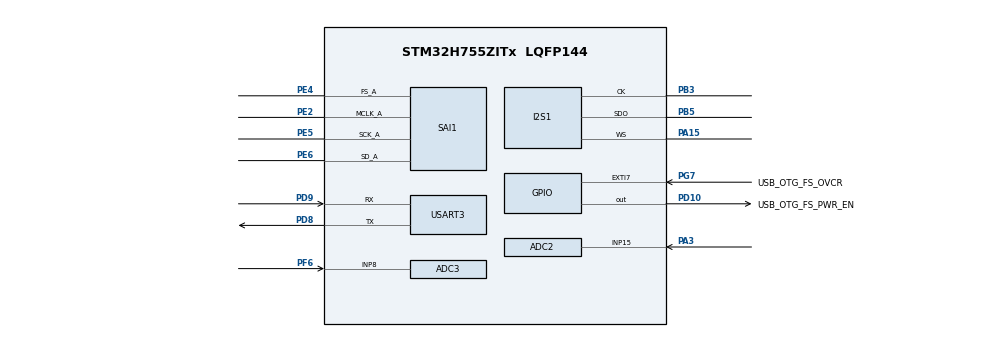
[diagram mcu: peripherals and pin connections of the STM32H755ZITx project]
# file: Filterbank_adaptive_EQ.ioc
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ADC2.Channel-2\#ChannelRegularConversion=ADC_CHANNEL_15
ADC2.NbrOfConversionFlag=1
ADC2.OffsetNumber-2\#ChannelRegularConversion=ADC_OFFSET_NONE
ADC2.OffsetSignedSaturation-2\#ChannelRegularConversion=DISABLE
ADC2.Rank-2\#ChannelRegularConversion=1
ADC2.SamplingTime-2\#ChannelRegularConversion=ADC_SAMPLETIME_1CYCLE_5
ADC3.Channel-0\#ChannelRegularConversion=ADC_CHANNEL_8
ADC3.NbrOfConversionFlag=1
ADC3.OffsetNumber-0\#ChannelRegularConversion=ADC_OFFSET_NONE
ADC3.OffsetSignedSaturation-0\#ChannelRegularConversion=DISABLE
ADC3.Rank-0\#ChannelRegularConversion=1
ADC3.SamplingTime-0\#ChannelRegularConversion=ADC_SAMPLETIME_1CYCLE_5
Bdma.ADC3.0.Direction=DMA_PERIPH_TO_MEMORY
Bdma.ADC3.0.EventEnable=DISABLE
Bdma.ADC3.0.Instance=BDMA_Channel0
Bdma.ADC3.0.MemDataAlignment=DMA_MDATAALIGN_HALFWORD
Bdma.ADC3.0.MemInc=DMA_MINC_ENABLE
Bdma.ADC3.0.Mode=DMA_CIRCULAR
Bdma.ADC3.0.PeriphDataAlignment=DMA_PDATAALIGN_HALFWORD
Bdma.ADC3.0.PeriphInc=DMA_PINC_DISABLE
Bdma.ADC3.0.Polarity=HAL_DMAMUX_REQ_GEN_RISING
Bdma.ADC3.0.Priority=DMA_PRIORITY_LOW
Bdma.ADC3.0.RequestNumber=1
Bdma.ADC3.0.SignalID=NONE
Bdma.ADC3.0.SyncEnable=DISABLE
Bdma.ADC3.0.SyncPolarity=HAL_DMAMUX_SYNC_NO_EVENT
Bdma.ADC3.0.SyncRequestNumber=1
Bdma.ADC3.0.SyncSignalID=NONE
Bdma.Request0=ADC3
Bdma.RequestsNb=1
CortexM4.IPs=FATFS_M4\:I,FREERTOS_M4\:I,IWDG2\:I,RCC,WWDG2\:I,DMA,BDMA,MDMA,NVIC2\:I,USART3,DEBUG,PDM2PCM_M4\:I,PWR,RESMGR_UTILITY,SYS_M4\:I,USB_DEVICE_M4\:I,USB_HOST_M4\:I,CORTEX_M4\:I,GPIO,OPENAMP_M4\:I,VREFBUF,NUCLEO-H755ZI-Q
CortexM7.IPs=FATFS_M7\:I,FREERTOS_M7\:I,IWDG1\:I,RCC\:I,WWDG1\:I,DMA\:I,BDMA\:I,MDMA\:I,NVIC1\:I,USART3\:I,USB_OTG_FS\:I,USB_OTG_FS1\:I,SYS\:I,CORTEX_M7\:I,DEBUG\:I,PDM2PCM_M7\:I,PWR\:I,RESMGR_UTILITY\:I,USB_DEVICE_M7\:I,USB_HOST_M7\:I,GPIO\:I,OPENAMP_M7\:I,VREFBUF\:I,NUCLEO-H755ZI-Q\:I,SAI1\:I,I2S1\:I,ADC3\:I,ADC2\:I
Dma.ADC2.2.Direction=DMA_PERIPH_TO_MEMORY
Dma.ADC2.2.EventEnable=DISABLE
Dma.ADC2.2.FIFOMode=DMA_FIFOMODE_DISABLE
Dma.ADC2.2.Instance=DMA1_Stream3
Dma.ADC2.2.MemDataAlignment=DMA_MDATAALIGN_HALFWORD
Dma.ADC2.2.MemInc=DMA_MINC_ENABLE
Dma.ADC2.2.Mode=DMA_CIRCULAR
Dma.ADC2.2.PeriphDataAlignment=DMA_PDATAALIGN_HALFWORD
Dma.ADC2.2.PeriphInc=DMA_PINC_DISABLE
Dma.ADC2.2.Polarity=HAL_DMAMUX_REQ_GEN_RISING
Dma.ADC2.2.Priority=DMA_PRIORITY_LOW
Dma.ADC2.2.RequestNumber=1
Dma.ADC2.2.SignalID=NONE
Dma.ADC2.2.SyncEnable=DISABLE
Dma.ADC2.2.SyncPolarity=HAL_DMAMUX_SYNC_NO_EVENT
Dma.ADC2.2.SyncRequestNumber=1
Dma.ADC2.2.SyncSignalID=NONE
Dma.Request0=SAI1_A
Dma.Request1=SPI1_TX
Dma.Request2=ADC2
Dma.SAI1_A.0.Direction=DMA_PERIPH_TO_MEMORY
Dma.SAI1_A.0.EventEnable=DISABLE
Dma.SAI1_A.0.FIFOMode=DMA_FIFOMODE_DISABLE
Dma.SAI1_A.0.Instance=DMA1_Stream0
Dma.SAI1_A.0.MemDataAlignment=DMA_MDATAALIGN_HALFWORD
Dma.SAI1_A.0.MemInc=DMA_MINC_ENABLE
Dma.SAI1_A.0.Mode=DMA_CIRCULAR
Dma.SAI1_A.0.PeriphDataAlignment=DMA_PDATAALIGN_HALFWORD
Dma.SAI1_A.0.PeriphInc=DMA_PINC_DISABLE
Dma.SAI1_A.0.Polarity=HAL_DMAMUX_REQ_GEN_RISING
Dma.SAI1_A.0.Priority=DMA_PRIORITY_VERY_HIGH
Dma.SAI1_A.0.RequestNumber=1
Dma.SAI1_A.0.SignalID=NONE
Dma.SAI1_A.0.SyncEnable=DISABLE
Dma.SAI1_A.0.SyncPolarity=HAL_DMAMUX_SYNC_NO_EVENT
Dma.SAI1_A.0.SyncRequestNumber=1
Dma.SAI1_A.0.SyncSignalID=NONE
Dma.SPI1_TX.1.Direction=DMA_MEMORY_TO_PERIPH
Dma.SPI1_TX.1.EventEnable=DISABLE
Dma.SPI1_TX.1.FIFOMode=DMA_FIFOMODE_DISABLE
Dma.SPI1_TX.1.Instance=DMA1_Stream1
Dma.SPI1_TX.1.MemDataAlignment=DMA_MDATAALIGN_HALFWORD
Dma.SPI1_TX.1.MemInc=DMA_MINC_ENABLE
Dma.SPI1_TX.1.Mode=DMA_CIRCULAR
Dma.SPI1_TX.1.PeriphDataAlignment=DMA_PDATAALIGN_HALFWORD
Dma.SPI1_TX.1.PeriphInc=DMA_PINC_DISABLE
Dma.SPI1_TX.1.Polarity=HAL_DMAMUX_REQ_GEN_RISING
Dma.SPI1_TX.1.Priority=DMA_PRIORITY_VERY_HIGH
Dma.SPI1_TX.1.RequestNumber=1
Dma.SPI1_TX.1.SignalID=NONE
Dma.SPI1_TX.1.SyncEnable=DISABLE
Dma.SPI1_TX.1.SyncPolarity=HAL_DMAMUX_SYNC_NO_EVENT
Dma.SPI1_TX.1.SyncRequestNumber=1
Dma.SPI1_TX.1.SyncSignalID=NONE
I2S1.AudioFreq=I2S_AUDIOFREQ_44K
I2S1.CPOL=I2S_CPOL_LOW
I2S1.DataFormat=I2S_DATAFORMAT_16B_EXTENDED
I2S1.ErrorAudioFreq=0.22 %
I2S1.Instance=SPI$Index
I2S1.RealAudioFreq=44.101 KHz
Mcu.Family=STM32H7
Mcu.Name=STM32H755ZITx
Mcu.Package=LQFP144
NVIC1.BDMA_Channel0_IRQn=true\:0\:0\:false\:false\:true\:false\:true\:true
NVIC1.DMA1_Stream0_IRQn=true\:0\:0\:false\:false\:true\:false\:true\:true
NVIC1.DMA1_Stream1_IRQn=true\:0\:0\:false\:false\:true\:false\:true\:true
NVIC1.DMA1_Stream3_IRQn=true\:0\:0\:false\:false\:true\:false\:true\:true
NVIC1.PriorityGroup=NVIC_PRIORITYGROUP_4
NVIC2.PriorityGroup=NVIC_PRIORITYGROUP_4
PA1.PinAttribute=CortexM4
PA1.Signal=ETH_REF_CLK
PA11.PinAttribute=CortexM7
PA11.Signal=USB_OTG_FS_DM
PA12.PinAttribute=CortexM7
PA12.Signal=USB_OTG_FS_DP
PA15\ (JTDI).Mode=Half_Duplex_Master_Tx
PA15\ (JTDI).PinAttribute=CortexM7
PA15\ (JTDI).Signal=I2S1_WS
PA2.PinAttribute=CortexM4
PA2.Signal=ETH_MDIO
PA3.PinAttribute=CortexM7
PA3.Signal=ADCx_INP15
PA7.PinAttribute=CortexM4
PA7.Signal=ETH_CRS_DV
PA8.PinAttribute=CortexM7
PA8.Signal=USB_OTG_FS_SOF
PA9.PinAttribute=CortexM7
PA9.Signal=USB_OTG_FS_VBUS
PB10.PinAttribute=CortexM7
PB10.Signal=I2S2_CK
PB15.PinAttribute=CortexM7
PB15.Signal=I2S2_SDO
PB3\ (JTDO/TRACESWO).Mode=Half_Duplex_Master_Tx
PB3\ (JTDO/TRACESWO).PinAttribute=CortexM7
PB3\ (JTDO/TRACESWO).Signal=I2S1_CK
PB4\ (NJTRST).PinAttribute=CortexM7
PB4\ (NJTRST).Signal=I2S2_WS
PB5.Mode=Half_Duplex_Master_Tx
PB5.PinAttribute=CortexM7
PB5.Signal=I2S1_SDO
PC14-OSC32_IN\ (OSC32_IN).PinAttribute=Free
PC14-OSC32_IN\ (OSC32_IN).Signal=RCC_OSC32_IN
PC15-OSC32_OUT\ (OSC32_OUT).PinAttribute=Free
PC15-OSC32_OUT\ (OSC32_OUT).Signal=RCC_OSC32_OUT
PC5.PinAttribute=CortexM4
PC5.Signal=ETH_RXD1
PD10.GPIO_Label=USB_OTG_FS_PWR_EN
PD10.PinAttribute=Free
PD10.Signal=GPIO_Output
PD11.PinAttribute=CortexM7
PD11.Signal=SAI2_SD_A
PD12.PinAttribute=CortexM7
PD12.Signal=SAI2_FS_A
PD13.PinAttribute=CortexM7
PD13.Signal=SAI2_SCK_A
PD8.Mode=Asynchronous
PD8.PinAttribute=CortexM7
PD8.Signal=USART3_TX
PD9.Mode=Asynchronous
PD9.PinAttribute=CortexM7
PD9.Signal=USART3_RX
PE2.GPIO_Speed=GPIO_SPEED_FREQ_VERY_HIGH
PE2.Mode=SAI_A_MasterWithClock
PE2.PinAttribute=CortexM7
PE2.Signal=SAI1_MCLK_A
PE4.GPIO_Speed=GPIO_SPEED_FREQ_VERY_HIGH
PE4.Mode=SAI_A_MasterWithClock
PE4.PinAttribute=CortexM7
PE4.Signal=SAI1_FS_A
PE5.GPIO_Speed=GPIO_SPEED_FREQ_VERY_HIGH
PE5.Mode=SAI_A_MasterWithClock
PE5.PinAttribute=CortexM7
PE5.Signal=SAI1_SCK_A
PE6.GPIO_Speed=GPIO_SPEED_FREQ_VERY_HIGH
PE6.Mode=SAI_A_MasterWithClock
PE6.PinAttribute=CortexM7
PE6.Signal=SAI1_SD_A
PF6.Mode=IN8-Single-Ended
PF6.PinAttribute=CortexM7
PF6.Signal=ADC3_INP8
PG11.PinAttribute=CortexM4
PG11.Signal=ETH_TX_EN
PG13.PinAttribute=CortexM4
PG13.Signal=ETH_TXD0
PG7.GPIO_Label=USB_OTG_FS_OVCR
PG7.PinAttribute=Free
PG7.Signal=GPXTI7
PH0-OSC_IN\ (PH0).Mode=HSE-External-Oscillator
PH0-OSC_IN\ (PH0).PinAttribute=Free
PH0-OSC_IN\ (PH0).Signal=RCC_OSC_IN
PH1-OSC_OUT\ (PH1).Mode=HSE-External-Oscillator
PH1-OSC_OUT\ (PH1).PinAttribute=Free
PH1-OSC_OUT\ (PH1).Signal=RCC_OSC_OUT
ProjectManager.HeapSize=M4-0x200,M7-0x200
ProjectManager.StackSize=M4-0x400,M7-0x400
ProjectManager.TargetToolchain=STM32CubeIDE
RCC.ADCFreq_Value=80000000
RCC.APB1Freq_Value=35281250
RCC.APB2Freq_Value=70562500
RCC.APB3Freq_Value=70562500
RCC.APB4Freq_Value=70562500
RCC.CortexFreq_Value=141125000
RCC.D1PPRE=RCC_APB3_DIV2
RCC.D2PPRE1=RCC_APB1_DIV4
RCC.D2PPRE2=RCC_APB2_DIV2
RCC.D3PPRE=RCC_APB4_DIV2
RCC.DIVM1=4
RCC.DIVM2=4
RCC.DIVN1=17
RCC.DIVN2=10
RCC.DIVQ1=25
RCC.HCLKFreq_Value=141125000
RCC.HSE_VALUE=8000000
RCC.PLL2FRACN=0
RCC.PLL3FRACN=0
RCC.PLLFRACN=5248
RCC.SYSCLKFreq_VALUE=141125000
RCC.SYSCLKSource=RCC_SYSCLKSOURCE_PLLCLK
RCC.SupplySource=PWR_DIRECT_SMPS_SUPPLY
RCC.USBFreq_Value=11290000
SAI1.AudioFrequency-SAI_A_MasterWithClock=SAI_AUDIO_FREQUENCY_44K
SAI1.AudioMode-SAI_A_MasterWithClock=SAI_MODEMASTER_RX
SAI1.BasicDataSize-SAI_A_MasterWithClock=SAI_PROTOCOL_DATASIZE_16BITEXTENDED
SAI1.ErrorAudioFreq-SAI_A_MasterWithClock=0.0 %
SAI1.InitProtocol-SAI_A_MasterWithClock=Enable
SAI1.Instance-SAI_A_MasterWithClock=SAI$Index_Block_A
SAI1.MClockEnable-SAI_A_MasterWithClock=SAI_MASTERCLOCK_ENABLE
SAI1.RealAudioFreq-SAI_A_MasterWithClock=44.101 KHz
SAI1.VirtualMode-SAI_A_MasterWithClock=VM_MASTER
SAI1.VirtualProtocol-SAI_A_BASIC=VM_BASIC_PROTOCOL
SH.ADCx_INP15.0=ADC2_INP15,IN15-Single-Ended
USART3.VirtualMode-Asynchronous=VM_ASYNC
VP_SAI1_VP_$IpInstance_SAIA_SAI_BASIC.Mode=SAI_A_BASIC
VP_SYS_M4_VS_Systick.Mode=SysTick
board=NUCLEO-H755ZI-Q

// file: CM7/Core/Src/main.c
/* USER CODE BEGIN Header */
/**
 * @file           : main.c
 * @brief          : Audio path and room equalizer control
 */
/* USER CODE END Header */
#include "main.h"
#include "adc.h"
#include "bdma.h"
#include "dma.h"
#include "i2s.h"
#include "sai.h"
#include "usart.h"
#include "gpio.h"

/* USER CODE BEGIN Includes */
#include <math.h>
#include <string.h>
#include <stdio.h>
#include "mic_eq_coeffs.h"   /* generated by Tools/EQ_to_BIQUAD.py */
#include "room_eq.h"
/* USER CODE END Includes */

/* USER CODE BEGIN PD */
/* DMA buffer sizes: circular buffers that are processed half by half (ping-pong) */
#define I2S_HALF_FRAMES         256U                         /* stereo frames per half-buffer */
#define I2S_HALF_SAMPLES        (I2S_HALF_FRAMES * 2U)       /* L+R samples per half-buffer */
#define I2S_BUFFER_SAMPLES      (I2S_HALF_SAMPLES * 2U)      /* both halves */

/* Gain per source in dB (left and right), the output is saturated */
#define MIC_GAIN_DB             2.0f        /* PCM1808, SAI1 A */
#define ADC_GAIN_DB             2.0f        /* analog mics, ADC3 + ADC2 */
/* PCM1808 (SAI1 A: PE2 SCKI, PE4 LRCK, PE5 BCK, PE6 DOUT): audio source, equalized and played.
 * Analog mics (left PF6 / ADC3_INP8, right PA3 / ADC2_INP15): measurement microphones of the room equalizer.
 * B1 (PC13): short press = room adaptation run / freeze (LD2 lit = running), hold 1 s = room equalizer on / off
 *            incl. the manual filters (LD3 lit = off). The PCM1808 / mic correction filters always stay on.
 * Serial terminal (USART3, 115200): see Gain_HandleUart(). */
#define MIC_SRC_I2S             0U       /* PCM1808: source, played */
#define MIC_SRC_ADC             1U       /* analog mics: only measured */
#define MIC_SRC_COUNT           2U
#define ADC_HALF_SAMPLES        I2S_HALF_FRAMES              /* per ADC channel, same block length as SAI */
/* Master output volume in dB, applied after the per-source gains (DAC full scale = 2.1 Vrms per channel) */
#define OUTPUT_GAIN_DB          -5.0f
/* DAC output: I2S1 (PB3 BCK, PA15 LRCK, PB5 DIN), plain stereo: left channel on OUTL, right channel on OUTR. */
#define hi2sOut                 hi2s1
/* Recording marker: a short pulse on both outputs (after the room equalizer, independent of gain and mute) when the
 * adaptation is started (1 pulse) or frozen (2 pulses). A start is delayed until the marker has left the mic frames. */
#define MARKER_FREQ_HZ          19000.0f
#define MARKER_AMP              0.9f                         /* peak, fraction of full scale */
#define MARKER_BURST_MS         5U                           /* length of one pulse and of the gap between two pulses */
#define MARKER_RAMP_US          500U                         /* fade in / out */
#define MARKER_SETTLE_MS        400U                         /* delay of the adaptation start after the marker */
#define MARKER_BURST_SAMPLES    ((uint32_t)(ROOMEQ_FS_HZ * MARKER_BURST_MS / 1000.0))
#define MARKER_RAMP_SAMPLES     ((uint32_t)(ROOMEQ_FS_HZ * MARKER_RAMP_US / 1000000.0))
/* USER CODE END PD */

/* USER CODE BEGIN PV */
/* Buffer filled by the PCM1808 (SAI RX DMA), stereo interleaved L,R */
int16_t micRxBuffer[I2S_BUFFER_SAMPLES];

/* Buffer read by the Speaker/DAC (I2S TX DMA), stereo interleaved L,R */
int16_t i2sTxBuffer[I2S_BUFFER_SAMPLES];

volatile uint32_t rxCount = 0, txCount = 0;
volatile int16_t  micPeak = 0;              /* peak |sample| of last block, for UART debug */
volatile int16_t  rawMin[2], rawMax[2];     /* raw SAI data per slot (L,R) of last block */
volatile uint32_t saiSr = 0;                /* SAI1 Block A status register, sticky errors */

/* Analog mics: channel 0 = ADC3 / PF6 (left), channel 1 = ADC2 / PA3 (right).
 * ADC3 is served by the BDMA, which can only reach SRAM4 -> .sram4 section (see linker script).
 * ADC2 is served by DMA1 (stream 3), which reaches the normal AXI SRAM. */
__attribute__((section(".sram4"), aligned(32))) uint16_t adcRxBuffer[ADC_HALF_SAMPLES * 2U];
__attribute__((aligned(32))) uint16_t adc2RxBuffer[ADC_HALF_SAMPLES * 2U];
/* The two ADCs deliver their halves in separate callbacks: collect them here, process when both are in */
static int16_t  adcPcm[2][2][ADC_HALF_SAMPLES];     /* [half][channel][sample], signed */
static uint8_t  adcReady[2];                        /* per half: bit 0 = ADC3 in, bit 1 = ADC2 in */
volatile uint32_t adcCount = 0;
volatile uint16_t adcMin[2], adcMax[2];             /* raw ADC range of last block per channel, for UART debug */

static uint32_t lastPrint = 0;
/* Per source (index = MIC_SRC_xxx) */
static int32_t        srcDc[MIC_SRC_COUNT][2];           /* DC blocker states per channel, Q8 */
static float          srcGain[MIC_SRC_COUNT];            /* linear gain, from *_GAIN_DB at startup */
static float          outGain = 1.0f;                    /* master volume, from OUTPUT_GAIN_DB */
static volatile float lvlSumSq[MIC_SRC_COUNT][2];        /* sum of squares BEFORE gain per channel, for the level meter */
static volatile uint32_t lvlCount[MIC_SRC_COUNT];

/* Frequency-response correction: one biquad cascade per source and channel (coefficients from Tools/EQ_to_BIQUAD.py).
 * The PCM1808 cascades are applied in Audio_ProcessBlock(), the ADC (mic) cascades in the analysis of room_eq.c.
 * Double precision: the low-frequency sections have poles very close to the unit circle. */
static const struct { const MicEqBiquad *bq; uint32_t n; } eqTable[MIC_SRC_COUNT][2] = {
    { { micEq_pcmL, MIC_EQ_PCML_N }, { micEq_pcmR, MIC_EQ_PCMR_N } },    /* MIC_SRC_I2S */
    { { micEq_adcL, MIC_EQ_ADCL_N }, { micEq_adcR, MIC_EQ_ADCR_N } },    /* MIC_SRC_ADC */
};
/* Coefficients and states live in DTCM (zero wait states; the data cache is off, so flash / AXI SRAM accesses are slow).
 * The coefficients are copied from flash in Eq_Init(). */
__attribute__((section(".dtcm"), aligned(8))) static MicEqBiquad eqCoef[MIC_SRC_COUNT][2][MIC_EQ_MAX_SECTIONS];
__attribute__((section(".dtcm"), aligned(8))) static double      eqState[MIC_SRC_COUNT][2][MIC_EQ_MAX_SECTIONS][2];   /* transposed DF2: z1, z2 */
volatile uint32_t procCyclesMax = 0;    /* worst Audio_ProcessBlock time, PCM1808 path incl. room equalizer, CPU cycles */
volatile uint32_t procMicCyclesMax = 0; /* worst time of the mic path */
volatile uint32_t pollCyclesMax = 0;    /* worst room analysis frame (main loop) */
static volatile uint8_t eqReset[MIC_SRC_COUNT];   /* start the correction filters of a source from zero state */

/* Room equalizer in the audio path: up to ROOMEQ_MAX_FILTERS peaking biquads, same coefficients for L and R. The coefficients
 * are designed by room_eq.c in the main loop and copied here by the audio interrupt.
 * Single precision for speed (the Cortex-M7 FPU pipelines float but not double); the float noise stays below about -90 dB. */
typedef struct { float b0, b1, b2, a1, a2; } RoomBqF;
__attribute__((section(".dtcm"), aligned(8))) static RoomBqF roomBq[ROOMEQ_MAX_FILTERS];
__attribute__((section(".dtcm"), aligned(8))) static float   roomState[2][ROOMEQ_MAX_FILTERS][2];
/* The lowest sections (poles very close to the unit circle) stay in double precision: float noise there is about 15 dB higher. */
#define ROOM_DBL_FREQ_HZ        120.0
#define ROOM_DBL_MAX            4U
__attribute__((section(".dtcm"), aligned(8))) static RoomEqBiquad roomBqD[ROOM_DBL_MAX];
__attribute__((section(".dtcm"), aligned(8))) static double       roomStateD[2][ROOM_DBL_MAX][2];
static uint32_t         roomND = 0;
static uint32_t         roomN = 0;
static uint32_t         roomSeq = 0xFFFFFFFFu;
/* Manual peaking filters (keys k/x/X/j/J/l/L/o) for narrow room modes that the band equalizer cannot resolve.
 * Same stage as the adaptive equalizer (double precision, both channels), switched with 'q' together with it. */
#define ROOM_MANUAL_MAX         3U
typedef struct { uint8_t on; float freq, gainDb, q; } ManualPk;
static ManualPk manualPk[ROOM_MANUAL_MAX] = { { 1, 84.5f, 0.0f, 6.0f }, { 0, 50.0f, 0.0f, 6.0f }, { 0, 120.0f, 0.0f, 6.0f } };
static uint32_t manualSel = 0;
static RoomEqBiquad manualBuf[2][ROOM_MANUAL_MAX];            /* main loop writes the idle buffer, then flips */
static uint32_t     manualCount[2];
static volatile uint32_t manualCur = 0, manualSeq = 0;
__attribute__((section(".dtcm"), aligned(8))) static RoomEqBiquad manBq[ROOM_MANUAL_MAX];
__attribute__((section(".dtcm"), aligned(8))) static double       manState[2][ROOM_MANUAL_MAX][2];
static uint32_t         manN = 0, manSeqSeen = 0xFFFFFFFFu;
static volatile uint8_t roomMute = 0;   /* output muted while the mics measure their noise floor */
static uint32_t         muteUntil = 0;
static volatile uint8_t roomShed = 0;   /* set when a block took too long: the room equalizer was switched off */
static volatile uint32_t shedCycles = 0;
static volatile uint8_t errSai = 0, errAdc = 0, errI2s = 0;   /* set by the error callbacks, printed in the main loop */
static volatile uint8_t roomReset = 0;
static volatile uint8_t markerReq = 0;  /* number of marker pulses requested by the main loop (1 = adaptation started, 2 = frozen) */
static uint8_t          markerBursts = 0;                    /* owned by the audio interrupt */
static uint32_t         markerPos = 0;
static float            markerPhase = 0.0f;
static uint8_t          adaptPending = 0;                    /* start requested, waiting for the marker to fade out */
static uint32_t         adaptStartAt = 0;
static volatile uint8_t roomBypass = 0; /* 1 = room equalizer off (B1 hold / 'q' / overload protection), LD3 red lit */
/* USER CODE END PV */

void SystemClock_Config(void);
void PeriphCommonClock_Config(void);
/* USER CODE BEGIN PFP */
void UART_Print(char *str);
void Error_Handler(void);
/* USER CODE END PFP */

/* USER CODE BEGIN 0 */

/**
 * @brief  Return the half of i2sTxBuffer that the I2S DMA is NOT playing right now.
 *         SAI1, I2S and TIM6 (ADC trigger) share PLL1, so every source delivers one block per TX half-buffer.
 *         The sources are started in the middle of a TX half (Audio_WaitTxMidHalf), which leaves half a block of margin.
 */
static int16_t *Audio_TxHalfToFill(void)
{
    uint32_t txRemaining = __HAL_DMA_GET_COUNTER(hi2sOut.hdmatx);        /* counts down */
    return (txRemaining > I2S_HALF_SAMPLES) ? &i2sTxBuffer[I2S_HALF_SAMPLES]  /* TX plays half 0 */
                                            : &i2sTxBuffer[0];                /* TX plays half 1 */
}

static inline __attribute__((always_inline)) float Audio_Clip(float v)
{
    if (v >  32767.0f) return  32767.0f;
    if (v < -32768.0f) return -32768.0f;
    return v;
}

/* next sample of the marker (burst, gap, burst ...; 0 when idle), called once per output frame while markerBursts != 0 */
static float Marker_Next(void)
{
    const uint32_t B = MARKER_BURST_SAMPLES, R = MARKER_RAMP_SAMPLES;
    if (markerPos >= (2U * markerBursts - 1U) * B)
    {
        markerBursts = 0U;
        return 0.0f;
    }
    const uint32_t o = markerPos % (2U * B);                 /* position inside burst + gap */
    markerPos++;
    if (o >= B) return 0.0f;                                 /* gap */
    float env = 1.0f;
    if (o < R)                env = (float)o / (float)R;
    else if (o >= B - R)      env = (float)(B - 1U - o) / (float)R;
    markerPhase += 6.2831853f * MARKER_FREQ_HZ / (float)ROOMEQ_FS_HZ;
    if (markerPhase >= 6.2831853f) markerPhase -= 6.2831853f;
    return MARKER_AMP * 32767.0f * env * sinf(markerPhase);
}

/**
 * @brief  Process one block (I2S_HALF_FRAMES samples) of a stereo input: DC blocker, level measurement and
 *         the correction filters (frequency response of the PCM1808; the analog mics are corrected in the analysis).
 *         - MIC_SRC_I2S (PCM1808) is the audio source: room equalizer, gain, saturation and output to
 *           the I2S TX buffer. The mono sum of the corrected PCM1808 signal BEFORE the room equalizer is the reference of the room analysis.
 *         - MIC_SRC_ADC (analog mics) are the measurement microphones: they only feed the room analysis.
 * @param  source  MIC_SRC_xxx
 * @param  dst     TX half from Audio_TxHalfToFill(), taken at callback ENTRY (NULL for the mics)
 * @param  srcL    first left sample (mic 1 / PF6)
 * @param  srcR    first right sample (mic 2 / PA3)
 * @param  stride  distance between samples of one channel (2 = interleaved stereo, 1 = separate buffers)
 */
__attribute__((optimize("O2")))
static void Audio_ProcessBlock(uint32_t source, int16_t *dst,
                               const int16_t *srcL, const int16_t *srcR, uint32_t stride)
{
    const uint32_t t0    = DWT->CYCCNT;
    const uint8_t  isOut = (source == MIC_SRC_I2S);
    const float    g     = roomMute ? 0.0f : srcGain[source] * outGain;
    int32_t        dcL   = srcDc[source][0];
    int32_t        dcR   = srcDc[source][1];
    float          sumL  = 0.0f;
    float          sumR  = 0.0f;
    int16_t        peak  = 0;
    int16_t        blkL[I2S_HALF_FRAMES], blkR[I2S_HALF_FRAMES];    /* mic samples for the analysis */

    /* The PCM1808 correction runs here; the analog mics are corrected in the frequency domain in room_eq.c */
    const MicEqBiquad *bqL = eqCoef[source][0];
    const MicEqBiquad *bqR = eqCoef[source][1];
    const uint32_t     nL  = isOut ? eqTable[source][0].n : 0U;
    const uint32_t     nR  = isOut ? eqTable[source][1].n : 0U;
    double (*zL)[2]        = eqState[source][0];
    double (*zR)[2]        = eqState[source][1];

    if (eqReset[source])
    {
        memset(eqState[source], 0, sizeof(eqState[source]));
        eqReset[source] = 0U;
    }

    const RoomBqF *rbq = roomBq;
    uint32_t       rn  = 0U, mn = 0U;
    double (*mdL)[2]   = manState[0];
    double (*mdR)[2]   = manState[1];
    float (*rzL)[2]    = roomState[0];
    float (*rzR)[2]    = roomState[1];
    double (*rdL)[2]   = roomStateD[0];
    double (*rdR)[2]   = roomStateD[1];
    if (isOut)
    {
        const uint32_t seq = RoomEq_CoefSeq();                 /* new room equalizer from the main loop? */
        if (seq != roomSeq)
        {
            const RoomEqCoefs *c = RoomEq_Coefs();
            roomN  = c->n;
            roomND = 0;
            while (roomND < c->n && roomND < ROOM_DBL_MAX && RoomEq_FilterFreq(roomND) < ROOM_DBL_FREQ_HZ)
            {
                roomBqD[roomND] = c->bq[roomND];
                roomND++;
            }
            for (uint32_t k = 0; k < c->n; k++)
            {
                roomBq[k].b0 = (float)c->bq[k].b0;  roomBq[k].b1 = (float)c->bq[k].b1;  roomBq[k].b2 = (float)c->bq[k].b2;
                roomBq[k].a1 = (float)c->bq[k].a1;  roomBq[k].a2 = (float)c->bq[k].a2;
            }
            roomSeq = seq;
        }
        if (markerReq)                                          /* marker requested by the main loop */
        {
            markerBursts = markerReq;
            markerReq    = 0U;
            markerPos    = 0U;
            markerPhase  = 0.0f;
        }
        const uint32_t msq = manualSeq;
        if (msq != manSeqSeen)
        {
            const uint32_t cur = manualCur;
            manN = manualCount[cur];
            for (uint32_t k = 0; k < manN; k++) manBq[k] = manualBuf[cur][k];
            manSeqSeen = msq;
        }
        if (roomReset)
        {
            memset(roomState, 0, sizeof(roomState));
            memset(roomStateD, 0, sizeof(roomStateD));
            memset(manState, 0, sizeof(manState));
            roomReset = 0U;
        }
        rn = roomBypass ? 0U : roomN;
        mn = roomBypass ? 0U : manN;
    }

    for (uint32_t i = 0; i < I2S_HALF_FRAMES; i++)
    {
        int32_t xl = srcL[i * stride];
        int32_t xr = srcR[i * stride];

        /* one-pole DC blocker: dc += (x - dc) / 256 */
        dcL += ((xl << 8) - dcL) >> 8;
        dcR += ((xr << 8) - dcR) >> 8;
        float dl = (float)(xl - (dcL >> 8));
        float dr = (float)(xr - (dcR >> 8));
        sumL += dl * dl;
        sumR += dr * dr;

        /* frequency-response correction (the level meter above stays uncorrected) */
        double ql = (double)dl;
        double qr = (double)dr;
        for (uint32_t k = 0; k < nL; k++)
        {
            double y = bqL[k].b0 * ql + zL[k][0];
            zL[k][0] = bqL[k].b1 * ql - bqL[k].a1 * y + zL[k][1];
            zL[k][1] = bqL[k].b2 * ql - bqL[k].a2 * y;
            ql = y;
        }
        for (uint32_t k = 0; k < nR; k++)
        {
            double y = bqR[k].b0 * qr + zR[k][0];
            zR[k][0] = bqR[k].b1 * qr - bqR[k].a1 * y + zR[k][1];
            zR[k][1] = bqR[k].b2 * qr - bqR[k].a2 * y;
            qr = y;
        }

        if (isOut)
        {
            /* reference of the room analysis: mono sum of the corrected input before the equalizer, with the output gain (0 while muted) */
            blkL[i] = (int16_t)Audio_Clip((float)(0.5 * (ql + qr)) * g);
            /* room equalizer: the same filters on both channels */
            const uint32_t nd = (rn < roomND) ? rn : roomND;
            for (uint32_t k = 0; k < nd; k++)                      /* lowest sections in double precision */
            {
                double y = roomBqD[k].b0 * ql + rdL[k][0];
                rdL[k][0] = roomBqD[k].b1 * ql - roomBqD[k].a1 * y + rdL[k][1];
                rdL[k][1] = roomBqD[k].b2 * ql - roomBqD[k].a2 * y;
                ql = y;
                y = roomBqD[k].b0 * qr + rdR[k][0];
                rdR[k][0] = roomBqD[k].b1 * qr - roomBqD[k].a1 * y + rdR[k][1];
                rdR[k][1] = roomBqD[k].b2 * qr - roomBqD[k].a2 * y;
                qr = y;
            }
            for (uint32_t k = 0; k < mn; k++)                      /* manual peaking filters, double precision */
            {
                double y = manBq[k].b0 * ql + mdL[k][0];
                mdL[k][0] = manBq[k].b1 * ql - manBq[k].a1 * y + mdL[k][1];
                mdL[k][1] = manBq[k].b2 * ql - manBq[k].a2 * y;
                ql = y;
                y = manBq[k].b0 * qr + mdR[k][0];
                mdR[k][0] = manBq[k].b1 * qr - manBq[k].a1 * y + mdR[k][1];
                mdR[k][1] = manBq[k].b2 * qr - manBq[k].a2 * y;
                qr = y;
            }
            float fl = (float)ql, fr = (float)qr;
            for (uint32_t k = nd; k < rn; k++)
            {
                const float b0 = rbq[k].b0, b1 = rbq[k].b1, b2 = rbq[k].b2, a1 = rbq[k].a1, a2 = rbq[k].a2;
                const float yl_ = b0 * fl + rzL[k][0];
                const float yr_ = b0 * fr + rzR[k][0];
                rzL[k][0] = b1 * fl - a1 * yl_ + rzL[k][1];
                rzR[k][0] = b1 * fr - a1 * yr_ + rzR[k][1];
                rzL[k][1] = b2 * fl - a2 * yl_;
                rzR[k][1] = b2 * fr - a2 * yr_;
                fl = yl_;
                fr = yr_;
            }

            if (!(fl > -1.0e6f && fl < 1.0e6f && fr > -1.0e6f && fr < 1.0e6f))      /* NaN / Inf / runaway */
            {
                memset(roomState, 0, sizeof(roomState));
                memset(roomStateD, 0, sizeof(roomStateD));
                memset(manState, 0, sizeof(manState));
                fl = (float)ql;
                fr = (float)qr;
            }

            const float mk = markerBursts ? Marker_Next() : 0.0f;     /* recording marker, after the equalizer, not scaled by g */
            int16_t yl = (int16_t)Audio_Clip(fl * g + mk);
            int16_t yr = (int16_t)Audio_Clip(fr * g + mk);
            dst[2U * i]      = yl;         /* left  */
            dst[2U * i + 1U] = yr;         /* right */

            int16_t al = (int16_t)((yl < 0) ? -yl : yl);
            int16_t ar = (int16_t)((yr < 0) ? -yr : yr);
            if (al > peak) peak = al;
            if (ar > peak) peak = ar;
        }
        else
        {
            blkL[i] = (int16_t)Audio_Clip((float)ql);      /* corrected mic signal, no gain */
            blkR[i] = (int16_t)Audio_Clip((float)qr);
        }
    }
    srcDc[source][0] = dcL;
    srcDc[source][1] = dcR;

    lvlSumSq[source][0] += sumL;
    lvlSumSq[source][1] += sumR;
    lvlCount[source]    += I2S_HALF_FRAMES;

    if (isOut)
    {
        micPeak = peak;
        RoomEq_PushRef(blkL, I2S_HALF_FRAMES);             /* reference: filled before the equalizer in the sample loop above */

        uint32_t dt = DWT->CYCCNT - t0;
        if (dt > procCyclesMax) procCyclesMax = dt;

        /* load protection: a call that alone takes more than 75 % of the block time starves the main loop,
         * so the room equalizer is switched off and reported */
        if ((dt > (SystemCoreClock / 44100U) * I2S_HALF_FRAMES * 3U / 4U) && !roomBypass)
        {
            roomBypass = 1U;
            roomReset  = 1U;
            shedCycles = dt;
            roomShed   = 1U;
        }
    }
    else
    {
        RoomEq_PushMic(0U, blkL, I2S_HALF_FRAMES);
        RoomEq_PushMic(1U, blkR, I2S_HALF_FRAMES);

        uint32_t dt = DWT->CYCCNT - t0;
        if (dt > procMicCyclesMax) procMicCyclesMax = dt;
    }
}

/* One finished half of micRxBuffer (PCM1808, stereo slots: slot 0 = left, slot 1 = right) */
static void Audio_SaiBlock(const int16_t *src)
{
    int16_t *dst = Audio_TxHalfToFill();

    /* raw data, both slots, before DC blocker / gain */
    for (uint32_t ch = 0; ch < 2U; ch++)
    {
        int16_t mn = INT16_MAX, mx = INT16_MIN;
        for (uint32_t i = 0; i < I2S_HALF_FRAMES; i++)
        {
            int16_t v = src[2U * i + ch];
            if (v < mn) mn = v;
            if (v > mx) mx = v;
        }
        rawMin[ch] = mn;
        rawMax[ch] = mx;
    }
    saiSr |= SAI1_Block_A->SR;
    rxCount++;

    Audio_ProcessBlock(MIC_SRC_I2S, dst, &src[0], &src[1], 2U);
}

/**
 * @brief  One finished half of an ADC buffer (unsigned 16-bit mono). The left (ADC3) and
 *         right (ADC2) mic are triggered by the same TIM6 event but report through separate
 *         DMA callbacks; the block is processed as soon as both halves of the same index are in.
 * @param  ch    0 = ADC3 / PF6 (left), 1 = ADC2 / PA3 (right)
 * @param  half  0 = first half of the DMA buffer, 1 = second half
 */
static void Audio_AdcBlock(uint32_t ch, uint32_t half, const uint16_t *src)
{
    int16_t  *pcm = adcPcm[half][ch];
    uint16_t  mn = UINT16_MAX, mx = 0;

    for (uint32_t i = 0; i < ADC_HALF_SAMPLES; i++)
    {
        uint16_t v = src[i];
        if (v < mn) mn = v;
        if (v > mx) mx = v;
        pcm[i] = (int16_t)((int32_t)v - 32768);   /* 0..65535 -> signed, mic bias ~ VDD/2 ~ 0 */
    }
    adcMin[ch] = mn;
    adcMax[ch] = mx;

    adcReady[half] |= (uint8_t)(1U << ch);
    if (adcReady[half] != 3U) return;             /* wait for the other mic */
    adcReady[half] = 0U;
    adcCount++;

    Audio_ProcessBlock(MIC_SRC_ADC, NULL, adcPcm[half][0], adcPcm[half][1], 1U);
}

/* Fired by the HAL SAI IRQ handler when the first half of micRxBuffer is full */
void HAL_SAI_RxHalfCpltCallback(SAI_HandleTypeDef *hsai)
{
    if (hsai->Instance == hsai_BlockA1.Instance)
    {
        Audio_SaiBlock(&micRxBuffer[0]);
    }
}

/* Fired when the second half of micRxBuffer is full */
void HAL_SAI_RxCpltCallback(SAI_HandleTypeDef *hsai)
{
    if (hsai->Instance == hsai_BlockA1.Instance)
    {
        Audio_SaiBlock(&micRxBuffer[I2S_HALF_SAMPLES]);

        /* Toggle LD1 to show audio is flowing */
        HAL_GPIO_TogglePin(GPIOB, GPIO_PIN_0);
    }
}

/* Fired by the BDMA / DMA1 IRQ handler when the first half of an ADC buffer is full */
void HAL_ADC_ConvHalfCpltCallback(ADC_HandleTypeDef *hadc)
{
    if (hadc->Instance == ADC3)
    {
        Audio_AdcBlock(0U, 0U, &adcRxBuffer[0]);
    }
    else if (hadc->Instance == ADC2)
    {
        Audio_AdcBlock(1U, 0U, &adc2RxBuffer[0]);
    }
}

/* Fired when the second half of an ADC buffer is full */
void HAL_ADC_ConvCpltCallback(ADC_HandleTypeDef *hadc)
{
    if (hadc->Instance == ADC3)
    {
        Audio_AdcBlock(0U, 1U, &adcRxBuffer[ADC_HALF_SAMPLES]);
    }
    else if (hadc->Instance == ADC2)
    {
        Audio_AdcBlock(1U, 1U, &adc2RxBuffer[ADC_HALF_SAMPLES]);
    }
}

void HAL_ADC_ErrorCallback(ADC_HandleTypeDef *hadc)
{
    errAdc = 1U;                        /* never print (blocking) from an interrupt */
}

/**
 * @brief  Busy-wait until the I2S TX DMA is in the middle of a half-buffer.
 *         A source started right after this delivers its blocks half a block
 *         away from the TX half switch, and stays there (common PLL1 clock).
 */
static void Audio_WaitTxMidHalf(void)
{
    uint32_t pos;
    do
    {
        pos = __HAL_DMA_GET_COUNTER(hi2sOut.hdmatx) % I2S_HALF_SAMPLES;
    } while ((pos < I2S_HALF_SAMPLES / 2U - 16U) || (pos > I2S_HALF_SAMPLES / 2U + 16U));
}

/**
 * @brief  Reconfigure an ADC for audio: TIM6-triggered at fs, circular DMA, 16 bit, 8x oversampling.
 *         Kernel clock 80 MHz / 4 / 2 = 10 MHz (rev. V silicon halves it internally): one sample takes
 *         8 x (16.5 + 8.5) cycles = 20 us, which must stay below 1/fs = 22.7 us or triggers are skipped.
 *         Used for ADC3 (PF6, channel 8) and ADC2 (PA3, channel 15).
 */
static void Audio_ADC_Config(ADC_HandleTypeDef *hadc, uint32_t channel)
{
    ADC_ChannelConfTypeDef ch = {0};

    hadc->Init.ClockPrescaler           = ADC_CLOCK_ASYNC_DIV4;           /* PLL2P 80 MHz / 4 (/2 rev.V) */
    hadc->Init.Resolution               = ADC_RESOLUTION_16B;
    hadc->Init.ContinuousConvMode       = DISABLE;
    hadc->Init.ExternalTrigConv         = ADC_EXTERNALTRIG_T6_TRGO;
    hadc->Init.ExternalTrigConvEdge     = ADC_EXTERNALTRIGCONVEDGE_RISING;
    hadc->Init.ConversionDataManagement = ADC_CONVERSIONDATA_DMA_CIRCULAR;
    hadc->Init.Overrun                  = ADC_OVR_DATA_OVERWRITTEN;
    hadc->Init.OversamplingMode         = ENABLE;
    hadc->Init.Oversampling.Ratio                 = 8;
    hadc->Init.Oversampling.RightBitShift         = ADC_RIGHTBITSHIFT_3;
    hadc->Init.Oversampling.TriggeredMode         = ADC_TRIGGEREDMODE_SINGLE_TRIGGER;
    hadc->Init.Oversampling.OversamplingStopReset = ADC_REGOVERSAMPLING_CONTINUED_MODE;
    if (HAL_ADC_Init(hadc) != HAL_OK) Error_Handler();

    ch.Channel      = channel;
    ch.Rank         = ADC_REGULAR_RANK_1;
    ch.SamplingTime = ADC_SAMPLETIME_16CYCLES_5;
    ch.SingleDiff   = ADC_SINGLE_ENDED;
    ch.OffsetNumber = ADC_OFFSET_NONE;
    if (HAL_ADC_ConfigChannel(hadc, &ch) != HAL_OK) Error_Handler();

    if (HAL_ADCEx_Calibration_Start(hadc, ADC_CALIB_OFFSET_LINEARITY, ADC_SINGLE_ENDED) != HAL_OK)
        Error_Handler();
}

/**
 * @brief  Configure SAI1 Block A for the PCM1808 (slave, I2S, MD0/MD1/FMT = GND):
 *         master RX, 16 bit data in 32 bit slots (top 16 of the 24 PCM1808 bits) and the
 *         256 x fs master clock on PE2 = PCM1808 SCKI. Set here as well as in CubeMX so that a
 *         regenerated sai.c cannot turn the block back into a transmitter.
 */
static void Audio_SAI_Config(void)
{
    hsai_BlockA1.Init.AudioMode = SAI_MODEMASTER_RX;
    hsai_BlockA1.Init.MckOutput = SAI_MCK_OUTPUT_ENABLE;
    if (HAL_SAI_InitProtocol(&hsai_BlockA1, SAI_I2S_STANDARD, SAI_PROTOCOL_DATASIZE_16BITEXTENDED, 2) != HAL_OK)
    {
        Error_Handler();
    }

    /* The generated pin setup uses the low speed class, too slow for the 11.29 MHz MCLK: the output pins to the
     * PCM1808 (PE2, PE4, PE5) get the fastest edges; PE6 (DOUT) is an input. */
    GPIO_InitTypeDef io = {0};
    io.Pin       = GPIO_PIN_2 | GPIO_PIN_4 | GPIO_PIN_5;
    io.Mode      = GPIO_MODE_AF_PP;
    io.Pull      = GPIO_NOPULL;
    io.Speed     = GPIO_SPEED_FREQ_VERY_HIGH;
    io.Alternate = GPIO_AF6_SAI1;
    HAL_GPIO_Init(GPIOE, &io);
}

/**
 * @brief  TIM6 as ADC trigger at exactly the I2S/SAI sample rate.
 *         fs = PLL1Q / 256 and the timer clock also comes from PLL1, so
 *         ARR = timclk * 256 / PLL1Q (= 1600 here) gives zero drift.
 */
static void Audio_TIM6_Config(void)
{
    PLL1_ClocksTypeDef pll;
    HAL_RCCEx_GetPLL1ClockFreq(&pll);
    uint32_t timClk = 2U * HAL_RCC_GetPCLK1Freq();                        /* APB1 prescaler 4 -> x2 */
    uint32_t div    = (uint32_t)(((uint64_t)timClk * 256U + pll.PLL1_Q_Frequency / 2U)
                                 / pll.PLL1_Q_Frequency);

    __HAL_RCC_TIM6_CLK_ENABLE();
    TIM6->CR1 = 0;
    TIM6->PSC = 0;
    TIM6->ARR = div - 1U;
    TIM6->EGR = TIM_EGR_UG;             /* load PSC/ARR */
    TIM6->CR2 = TIM_CR2_MMS_1;          /* TRGO on update event */
}

void HAL_I2S_TxCpltCallback(I2S_HandleTypeDef *hi2s)
{
    if (hi2s->Instance == hi2sOut.Instance) { txCount++; }
}

void HAL_SAI_ErrorCallback(SAI_HandleTypeDef *hsai)
{
    errSai = 1U;
}

void HAL_I2S_ErrorCallback(I2S_HandleTypeDef *hi2s)
{
    errI2s = 1U;
}

static float Audio_Db(float lin)
{
    return (lin > 1e-9f) ? 20.0f * log10f(lin) : -200.0f;
}

/* LD2 (yellow): room adaptation running */
static void Room_ShowAdapt(void)
{
    HAL_GPIO_WritePin(GPIOE, GPIO_PIN_1, (RoomEq_GetAdapt() || adaptPending) ? GPIO_PIN_SET : GPIO_PIN_RESET);
}

/* Run / freeze, both with a marker (1 pulse = run, 2 pulses = freeze). A start waits until the marker has faded
 * out, then Room_AdaptPoll() starts the adaptation. */
static void Room_ToggleAdapt(void)
{
    if (RoomEq_GetAdapt() || adaptPending)
    {
        adaptPending = 0U;
        RoomEq_SetAdapt(0);
        markerReq = 2U;
        UART_Print("Room adaptation: FROZEN (equalizer kept), marker: 2 pulses\r\n");
    }
    else
    {
        markerReq    = 1U;
        adaptStartAt = HAL_GetTick() + MARKER_BURST_MS + MARKER_SETTLE_MS;
        adaptPending = 1U;
        UART_Print("Room adaptation: RUNNING (LD2 lit), marker: 1 pulse, adaptation starts after it\r\n");
    }
    Room_ShowAdapt();
}

static void Room_AdaptPoll(void)
{
    if (adaptPending && (int32_t)(HAL_GetTick() - adaptStartAt) >= 0)
    {
        adaptPending = 0U;
        RoomEq_SetAdapt(1);
    }
}

/* Mute the output for 0.8 s: the reference is silent, the mics hear only their noise and the room analysis
 * learns the noise floor per band (bands that are not heard clearly above it are not adapted). */
static void Room_StartCal(void)
{
    RoomEq_ForgetNoiseFloor();
    muteUntil = HAL_GetTick() + 800U;
    roomMute  = 1U;
    UART_Print("Measuring the mic noise floor: output muted for 0.8 s\r\n");
}

/* room equalizer on / off for an A/B comparison (the adaptation keeps running) */
static void Room_ToggleBypass(void)
{
    roomReset = 1U;
    roomBypass = (uint8_t)!roomBypass;
    HAL_GPIO_WritePin(GPIOB, GPIO_PIN_14, roomBypass ? GPIO_PIN_SET : GPIO_PIN_RESET);       /* LD3 red lit = room EQ off */
    UART_Print(roomBypass ? "Room equalizer: OFF - clean input (LD3 lit)\r\n" : "Room equalizer: ON\r\n");
}

/* rebuild the manual filter coefficients from the slots and hand them to the audio interrupt */
static void Manual_Update(void)
{
    const uint32_t idle = 1U - manualCur;
    uint32_t n = 0;
    for (uint32_t i = 0; i < ROOM_MANUAL_MAX; i++)
        if (manualPk[i].on && fabsf(manualPk[i].gainDb) >= 0.05f)
            RoomEq_PeakCoefs((double)manualPk[i].freq, (double)manualPk[i].gainDb, (double)manualPk[i].q, &manualBuf[idle][n++]);
    manualCount[idle] = n;
    manualCur = idle;
    manualSeq = manualSeq + 1U;
}

static void Manual_Print(void)
{
    char m[100];
    for (uint32_t i = 0; i < ROOM_MANUAL_MAX; i++)
    {
        snprintf(m, sizeof(m), "%cmanual %u: %-3s %7.1f Hz  %+5.1f dB  Q %4.1f\r\n", (i == manualSel) ? '>' : ' ', (unsigned)(i + 1U),
                 manualPk[i].on ? "ON" : "off", (double)manualPk[i].freq, (double)manualPk[i].gainDb, (double)manualPk[i].q);
        UART_Print(m);
    }
}

/* k = next slot, x/X = frequency -/+ 0.5 Hz, j/J = gain -/+ 0.5 dB, l/L = Q smaller/larger, o = slot on/off */
static void Manual_Key(char c)
{
    ManualPk *p = &manualPk[manualSel];
    switch (c)
    {
        case 'k': manualSel = (manualSel + 1U) % ROOM_MANUAL_MAX; Manual_Print(); return;
        case 'x': p->freq -= 0.5f; break;
        case 'X': p->freq += 0.5f; break;
        case 'j': p->gainDb -= 0.5f; break;
        case 'J': p->gainDb += 0.5f; break;
        case 'l': p->q /= 1.15f; break;
        case 'L': p->q *= 1.15f; break;
        case 'o': p->on = (uint8_t)!p->on; break;
        default: return;
    }
    if (p->freq < 20.0f)  p->freq = 20.0f;
    if (p->freq > 500.0f) p->freq = 500.0f;
    if (p->gainDb < -24.0f) p->gainDb = -24.0f;
    if (p->gainDb >  12.0f) p->gainDb =  12.0f;
    if (p->q < 0.5f)  p->q = 0.5f;
    if (p->q > 30.0f) p->q = 30.0f;
    Manual_Update();
    Manual_Print();
}

static void Room_PrintState(void)
{
    char m[220];
    snprintf(m, sizeof(m), "Room EQ: adapt=%s eq=%s filters=%u frames=%lu noise floor=%s ref=%.0f mic1=%.0f mic2=%.0f LSB rms\r\n",
             RoomEq_GetAdapt() ? "run" : "frozen", roomBypass ? "OFF" : "on", (unsigned)ROOMEQ_MAX_FILTERS,
             (unsigned long)RoomEq_Frames(), RoomEq_NoiseFloorKnown() ? "known" : "NOT measured",
             (double)RoomEq_RefRms(), (double)RoomEq_MicRms(0U), (double)RoomEq_MicRms(1U));
    UART_Print(m);

    int n = snprintf(m, sizeof(m), "band Hz :");
    for (uint32_t b = 0; b < ROOMEQ_BANDS; b++) n += snprintf(&m[n], sizeof(m) - (size_t)n, "%6.0f", RoomEq_BandCenter(b));
    UART_Print(m); UART_Print("\r\n");
    n = snprintf(m, sizeof(m), "ref dB  :");                    /* reference level re its strongest band */
    for (uint32_t b = 0; b < ROOMEQ_BANDS; b++) n += snprintf(&m[n], sizeof(m) - (size_t)n, "%6.0f", (double)RoomEq_RefRelDb(b));
    UART_Print(m); UART_Print("\r\n");
    for (uint32_t r = 0; r < ROOMEQ_MICS; r++)                  /* mic SNR over its noise floor, '-' = band NOT used */
    {
        n = snprintf(m, sizeof(m), "snr%u dB :", (unsigned)(r + 1U));
        for (uint32_t b = 0; b < ROOMEQ_BANDS; b++)
            n += snprintf(&m[n], sizeof(m) - (size_t)n, "%5.0f%c", (double)RoomEq_BandSnrDb(r, b), RoomEq_BandValid(r, b) ? ' ' : '-');
        UART_Print(m); UART_Print("\r\n");
    }
    for (uint32_t r = 0; r < ROOMEQ_MICS; r++)
    {
        n = snprintf(m, sizeof(m), "mic%u dB :", (unsigned)(r + 1U));
        for (uint32_t b = 0; b < ROOMEQ_BANDS; b++) n += snprintf(&m[n], sizeof(m) - (size_t)n, "%+6.1f", (double)RoomEq_Weight(r, b));
        UART_Print(m); UART_Print("\r\n");
    }
    n = snprintf(m, sizeof(m), "filter Hz:");
    for (uint32_t i = 0; i < ROOMEQ_MAX_FILTERS; i++) n += snprintf(&m[n], sizeof(m) - (size_t)n, "%6.0f", RoomEq_FilterFreq(i));
    UART_Print(m); UART_Print("\r\n");
    n = snprintf(m, sizeof(m), "gain dB  :");
    for (uint32_t i = 0; i < ROOMEQ_MAX_FILTERS; i++) n += snprintf(&m[n], sizeof(m) - (size_t)n, "%+6.1f", RoomEq_FilterGainDb(i));
    UART_Print(m); UART_Print("\r\n");
    Manual_Print();
}

/**
 * @brief  Control from the ST-LINK serial terminal (USART3, 115200), non-blocking, one key per call.
 *           '+' / '-'  PCM1808 gain +1 dB / -1 dB      ']' / '['  +0.1 dB / -0.1 dB
 *           'g'        print the gain                   'r'        reset the gain to MIC_GAIN_DB
 *           'a'        room adaptation run / freeze (same as a short B1 press, LD2 lit = running)
 *           'q'        room equalizer on / off (same as holding B1; LD3 red lit = off)
 *           'z'        forget the room estimate (equalizer flat)
 *           'k' 'x' 'X' 'j' 'J' 'l' 'L' 'o'   manual peaking filters: next slot, frequency -/+ 0.5 Hz, gain -/+ 0.5 dB,
 *                      Q smaller/larger, slot on/off (for narrow room modes, e.g. 84.5 Hz)
 *           'n'        measure the mic noise floor again (output muted for 0.8 s)
 *           'w'        print band weights, band validity (ref level, mic SNR) and filter gains
 *         The gain is kept until reset/power-off; copy it into MIC_GAIN_DB to make it permanent.
 */
static void Gain_HandleUart(void)
{
    if (__HAL_UART_GET_FLAG(&huart3, UART_FLAG_ORE)) __HAL_UART_CLEAR_OREFLAG(&huart3);
    if (!__HAL_UART_GET_FLAG(&huart3, UART_FLAG_RXNE)) return;

    char  c    = (char)(huart3.Instance->RDR & 0xFFU);
    float step = 0.0f;

    switch (c)
    {
        case '+': step =  1.0f; break;
        case '-': step = -1.0f; break;
        case ']': step =  0.1f; break;
        case '[': step = -0.1f; break;
        case 'r': srcGain[MIC_SRC_I2S] = powf(10.0f, MIC_GAIN_DB / 20.0f); break;
        case 'g': break;
        case 'a': Room_ToggleAdapt(); return;
        case 'q': Room_ToggleBypass(); return;
        case 'z':
            RoomEq_Reset();
            roomReset = 1U;
            UART_Print("Room estimate reset (equalizer flat)\r\n");
            return;
        case 'w': Room_PrintState(); return;
        case 'n': Room_StartCal(); return;
        case 'k': case 'x': case 'X': case 'j': case 'J': case 'l': case 'L': case 'o': Manual_Key(c); return;
        default:  return;
    }

    if (step != 0.0f)
    {
        float db = Audio_Db(srcGain[MIC_SRC_I2S]) + step;
        if (db < -40.0f) db = -40.0f;
        if (db >  60.0f) db =  60.0f;
        srcGain[MIC_SRC_I2S] = powf(10.0f, db / 20.0f);   /* single float store: safe vs. the ISRs */
    }

    char m[60];
    snprintf(m, sizeof(m), "Gain PCM1808 = %.1f dB\r\n", (double)Audio_Db(srcGain[MIC_SRC_I2S]));
    UART_Print(m);
}

/**
 * @brief  Copy the correction coefficients from flash into DTCM and clear the filter states.
 */
static void Eq_Init(void)
{
    memset(eqState, 0, sizeof(eqState));
    for (uint32_t k = 0; k < MIC_SRC_COUNT; k++)
    {
        for (uint32_t c = 0; c < 2U; c++)
        {
            memcpy(eqCoef[k][c], eqTable[k][c].bq, eqTable[k][c].n * sizeof(MicEqBiquad));
        }
    }
}

/**
 * @brief  Blocking UART print helper over USART3
 */
void UART_Print(char *str)
{
    HAL_UART_Transmit(&huart3, (uint8_t *)str, strlen(str), HAL_MAX_DELAY);
}
/* USER CODE END 0 */

int main(void)
{

  /* USER CODE BEGIN 1 */
  SCB_EnableICache();     /* code runs from flash: instruction cache is safe (the D-cache stays off, DMA buffers) */
  /* USER CODE END 1 */
/* USER CODE BEGIN Boot_Mode_Sequence_0 */
#if defined(DUAL_CORE_BOOT_SYNC_SEQUENCE)
  int32_t timeout;
#endif /* DUAL_CORE_BOOT_SYNC_SEQUENCE */
/* USER CODE END Boot_Mode_Sequence_0 */

/* USER CODE BEGIN Boot_Mode_Sequence_1 */
#if defined(DUAL_CORE_BOOT_SYNC_SEQUENCE)
  /* Wait until CPU2 boots and enters in stop mode or timeout*/
  timeout = 0xFFFF;
  while((__HAL_RCC_GET_FLAG(RCC_FLAG_D2CKRDY) != RESET) && (timeout-- > 0));
  if ( timeout < 0 )
  {
  Error_Handler();
  }
#endif /* DUAL_CORE_BOOT_SYNC_SEQUENCE */
/* USER CODE END Boot_Mode_Sequence_1 */
  /* MCU Configuration--------------------------------------------------------*/

  /* Reset of all peripherals, Initializes the Flash interface and the Systick. */
  HAL_Init();

  /* Configure the system clock */
  SystemClock_Config();

  /* Configure the peripherals common clocks */
  PeriphCommonClock_Config();
/* USER CODE BEGIN Boot_Mode_Sequence_2 */
#if defined(DUAL_CORE_BOOT_SYNC_SEQUENCE)
/* When system initialization is finished, Cortex-M7 will release Cortex-M4 by means of
HSEM notification */
/*HW semaphore Clock enable*/
__HAL_RCC_HSEM_CLK_ENABLE();
/*Take HSEM */
HAL_HSEM_FastTake(HSEM_ID_0);
/*Release HSEM in order to notify the CPU2(CM4)*/
HAL_HSEM_Release(HSEM_ID_0,0);
/* wait until CPU2 wakes up from stop mode */
timeout = 0xFFFF;
while((__HAL_RCC_GET_FLAG(RCC_FLAG_D2CKRDY) == RESET) && (timeout-- > 0));
if ( timeout < 0 )
{
Error_Handler();
}
#endif /* DUAL_CORE_BOOT_SYNC_SEQUENCE */
/* USER CODE END Boot_Mode_Sequence_2 */

  /* Initialize all configured peripherals */
  MX_GPIO_Init();
  MX_DMA_Init();
  MX_BDMA_Init();
  MX_SAI1_Init();
  MX_USART3_UART_Init();
  MX_ADC3_Init();
  MX_I2S1_Init();
  MX_ADC2_Init();
  /* USER CODE BEGIN 2 */

    /* Initialize Debug LED on PB0 */
    __HAL_RCC_GPIOB_CLK_ENABLE();
    GPIO_InitTypeDef GPIO_InitStruct = {0};
    GPIO_InitStruct.Pin = GPIO_PIN_0;
    GPIO_InitStruct.Mode = GPIO_MODE_OUTPUT_PP;
    GPIO_InitStruct.Pull = GPIO_NOPULL;
    GPIO_InitStruct.Speed = GPIO_SPEED_FREQ_LOW;
    HAL_GPIO_Init(GPIOB, &GPIO_InitStruct);
    HAL_GPIO_WritePin(GPIOB, GPIO_PIN_0, GPIO_PIN_RESET); // Turn OFF LD1 initially

    /* start gains (dB -> linear) */
    srcGain[MIC_SRC_I2S] = powf(10.0f, MIC_GAIN_DB / 20.0f);
    srcGain[MIC_SRC_ADC] = powf(10.0f, ADC_GAIN_DB / 20.0f);
    outGain              = powf(10.0f, OUTPUT_GAIN_DB / 20.0f);

    /* DWT cycle counter: measures the processing time per block */
    CoreDebug->DEMCR |= CoreDebug_DEMCR_TRCENA_Msk;
    DWT->LAR = 0xC5ACCE55;                      /* unlock (Cortex-M7) */
    DWT->CYCCNT = 0;
    DWT->CTRL |= DWT_CTRL_CYCCNTENA_Msk;

    Eq_Init();
    memset(roomStateD, 0, sizeof(roomStateD));
    memset(manState, 0, sizeof(manState));
    memset(manBq, 0, sizeof(manBq));
    memset(roomBqD, 0, sizeof(roomBqD));
    memset(roomState, 0, sizeof(roomState));   /* .dtcm is not initialised: after a cold power-up it holds random bits, */
    memset(roomBq, 0, sizeof(roomBq));         /* and a NaN in an IIR state would never go away */
    RoomEq_Init();
    RoomEq_SetMicCorrection(0U, (const double *)micEq_adcL, MIC_EQ_ADCL_N);    /* mic 1 = PF6 */
    RoomEq_SetMicCorrection(1U, (const double *)micEq_adcR, MIC_EQ_ADCR_N);    /* mic 2 = PA3 */
    RoomEq_SetMicCorrectionEnabled(1);

    Audio_SAI_Config();                 /* PCM1808: SAI1 A master RX + MCLK on PE2 */

    /* 1. Start I2S TX DMA in CIRCULAR mode */
    /* This will continuously play whatever is inside i2sTxBuffer */

    memset(i2sTxBuffer, 0, sizeof(i2sTxBuffer));   /* silence until the first block */

    if (HAL_I2S_Transmit_DMA(&hi2sOut, (uint16_t *)i2sTxBuffer, I2S_BUFFER_SAMPLES) != HAL_OK)
    {
        UART_Print("I2S DMA TX failed!\r\n");
        Error_Handler();
    }

    /* 2. Start SAI RX DMA in CIRCULAR mode: PCM1808 (slave, I2S 24 bit, MD0/MD1/FMT = GND).
     * Block A is master: it supplies LRCK (PE4), BCK (PE5) and the 256 x fs system clock SCKI (PE2),
     * and fills micRxBuffer with the L/R samples from DOUT (PE6). */
    Audio_WaitTxMidHalf();
    if (HAL_SAI_Receive_DMA(&hsai_BlockA1, (uint8_t *)micRxBuffer, I2S_BUFFER_SAMPLES) != HAL_OK)
    {
        UART_Print("SAI DMA RX failed!\r\n");
        Error_Handler();
    }

    /* 3. Analog mics: ADC3 (PF6, left) and ADC2 (PA3, right) in circular DMA,
     *    conversions of both triggered by TIM6 at fs */
    Audio_ADC_Config(&hadc3, ADC_CHANNEL_8);
    Audio_ADC_Config(&hadc2, ADC_CHANNEL_15);
    Audio_TIM6_Config();
    if (HAL_ADC_Start_DMA(&hadc3, (uint32_t *)adcRxBuffer, ADC_HALF_SAMPLES * 2U) != HAL_OK)
    {
        UART_Print("ADC3 DMA failed!\r\n");
        Error_Handler();
    }
    if (HAL_ADC_Start_DMA(&hadc2, (uint32_t *)adc2RxBuffer, ADC_HALF_SAMPLES * 2U) != HAL_OK)
    {
        UART_Print("ADC2 DMA failed!\r\n");
        Error_Handler();
    }
    Audio_WaitTxMidHalf();
    TIM6->CR1 |= TIM_CR1_CEN;           /* first ADC trigger -> analog blocks start now */

    /* 4. User button B1 (PC13, high when pressed, external pull-down), LD2 (PE1), LD3 (PB14) */
    __HAL_RCC_GPIOC_CLK_ENABLE();
    __HAL_RCC_GPIOE_CLK_ENABLE();
    GPIO_InitStruct.Pin  = GPIO_PIN_13;
    GPIO_InitStruct.Mode = GPIO_MODE_INPUT;
    GPIO_InitStruct.Pull = GPIO_NOPULL;
    HAL_GPIO_Init(GPIOC, &GPIO_InitStruct);
    GPIO_InitStruct.Pin   = GPIO_PIN_1;
    GPIO_InitStruct.Mode  = GPIO_MODE_OUTPUT_PP;
    GPIO_InitStruct.Speed = GPIO_SPEED_FREQ_LOW;
    HAL_GPIO_Init(GPIOE, &GPIO_InitStruct);
    GPIO_InitStruct.Pin   = GPIO_PIN_14;                 /* LD3 red: lit = room equalizer bypassed */
    HAL_GPIO_Init(GPIOB, &GPIO_InitStruct);
    HAL_GPIO_WritePin(GPIOB, GPIO_PIN_14, roomBypass ? GPIO_PIN_SET : GPIO_PIN_RESET);
    Room_ShowAdapt();

    UART_Print("Room equalizer started: PCM1808 = source, analog mics PF6 / PA3 = measurement mics.\r\n");
    UART_Print("B1 short = adapt run/freeze, B1 hold = room equalizer on/off (LD3 lit = off). Keys: +/-/]/[ gain, a adapt, q room EQ on/off, z reset, n noise floor, w weights, k x X j J l L o manual notch\r\n");
    Room_StartCal();                    /* output stays muted for 0.8 s while the mics measure their noise floor */
  /* USER CODE END 2 */

  /* Infinite loop */
  /* USER CODE BEGIN WHILE */
    while (1)
    {
    	/* B1: short press = room adaptation run/freeze (acts on release), hold >= 1 s = room equalizer on/off (LD3) */
    	{
    	    static GPIO_PinState btnPrev = GPIO_PIN_RESET;
    	    static uint32_t btnTime = 0, pressStart = 0;
    	    static uint8_t  longDone = 0;
    	    GPIO_PinState btn = HAL_GPIO_ReadPin(GPIOC, GPIO_PIN_13);

    	    if ((btn != btnPrev) && (HAL_GetTick() - btnTime >= 50U))
    	    {
    	        btnTime = HAL_GetTick();
    	        btnPrev = btn;
    	        if (btn == GPIO_PIN_SET)
    	        {
    	            pressStart = HAL_GetTick();
    	            longDone   = 0;
    	        }
    	        else if (!longDone)
    	        {
    	            Room_ToggleAdapt();
    	        }
    	    }
    	    if ((btnPrev == GPIO_PIN_SET) && !longDone && (HAL_GetTick() - pressStart >= 1000U))
    	    {
    	        longDone = 1;
    	        Room_ToggleBypass();
    	    }
    	}

    	Gain_HandleUart();                      /* control keys from the serial terminal */

    	if (roomMute && (int32_t)(HAL_GetTick() - muteUntil) >= 0)
    	{
    	    roomMute = 0U;
    	    UART_Print(RoomEq_NoiseFloorKnown() ? "Noise floor measured, output on\r\n"
    	                                        : "Noise floor NOT measured (analysis not running?), output on\r\n");
    	}
    	if (roomShed)
    	{
    	    char m[100];
    	    snprintf(m, sizeof(m), "OVERLOAD: block took %lu us, room equalizer switched off ('q' to try again)\r\n",
    	             (unsigned long)(shedCycles / (SystemCoreClock / 1000000U)));
    	    roomShed = 0U;
    	    HAL_GPIO_WritePin(GPIOB, GPIO_PIN_14, GPIO_PIN_SET);        /* LD3: room equalizer is off */
    	    UART_Print(m);
    	}
    	if (errSai) { errSai = 0U; UART_Print("SAI error\r\n"); }
    	if (errAdc) { errAdc = 0U; UART_Print("ADC error\r\n"); }
    	if (errI2s) { errI2s = 0U; UART_Print("I2S error\r\n"); }

    	/* room analysis: one STFT frame (4096 samples, hop 3072) of reference + 2 mics -> new equalizer */
    	{
    	    Room_AdaptPoll();                      /* adaptation start after the marker */
    	    RoomEq_SetEqActive(!roomBypass);       /* bypassed equalizer = open loop: no adaptation */
    	    const uint32_t t0 = DWT->CYCCNT;
    	    if (RoomEq_Poll() != 0)
    	    {
    	        const uint32_t dt = DWT->CYCCNT - t0;
    	        if (dt > pollCyclesMax) pollCyclesMax = dt;
    	    }
    	}

    	/* Audio is handled entirely in the DMA callbacks; this is debug only.
    	 * Expected once per second: rx and adc ~ +172, tx ~ +86 (44.1 kHz / 256 frames). */
    	if (HAL_GetTick() - lastPrint >= 1000)
    	{
    	    lastPrint = HAL_GetTick();

    	    char m[240];
    	    snprintf(m, sizeof(m), "PCM L[%d..%d] R[%d..%d] mics L[%u..%u] R[%u..%u] | rx=%lu adc=%lu tx=%lu peak=%d | "
    	             "pcm=%luus mic=%luus poll=%luus (block 5805us)\r\n",
    	             (int)rawMin[0], (int)rawMax[0], (int)rawMin[1], (int)rawMax[1],
    	             (unsigned)adcMin[0], (unsigned)adcMax[0], (unsigned)adcMin[1], (unsigned)adcMax[1],
    	             (unsigned long)rxCount, (unsigned long)adcCount,
    	             (unsigned long)txCount, (int)micPeak,
    	             (unsigned long)(procCyclesMax / (SystemCoreClock / 1000000U)),
    	             (unsigned long)(procMicCyclesMax / (SystemCoreClock / 1000000U)),
    	             (unsigned long)(pollCyclesMax / (SystemCoreClock / 1000000U)));
    	    procCyclesMax = 0;
    	    procMicCyclesMax = 0;
    	    pollCyclesMax = 0;
    	    UART_Print(m);

    	    snprintf(m, sizeof(m), "room: adapt=%s eq=%s filters=%u frames=%lu noise floor=%s ref=%.0f mic1=%.0f mic2=%.0f LSB rms | used bands %u/%u (need %u), error %.1f/%.1f dB\r\n",
    	             RoomEq_GetAdapt() ? "run" : "frozen", roomBypass ? "OFF" : "on", (unsigned)ROOMEQ_MAX_FILTERS,
    	             (unsigned long)RoomEq_Frames(), RoomEq_NoiseFloorKnown() ? "known" : "NOT measured",
    	             (double)RoomEq_RefRms(), (double)RoomEq_MicRms(0U), (double)RoomEq_MicRms(1U),
    	             (unsigned)RoomEq_ValidBands(0U), (unsigned)RoomEq_ValidBands(1U), (unsigned)ROOMEQ_MIN_VALID_BANDS,
    	             (double)RoomEq_ErrRmsDb(0U), (double)RoomEq_ErrRmsDb(1U));
    	    UART_Print(m);

    	    /* level meter: RMS of the last second per channel; PCM1808 as it sounds at the output (raw x gain), mics raw */
    	    float out[MIC_SRC_COUNT][2];
    	    __disable_irq();
    	    for (uint32_t k = 0; k < MIC_SRC_COUNT; k++)
    	    {
    	        for (uint32_t c = 0; c < 2U; c++)
    	        {
    	            float rms = (lvlCount[k] > 0U) ? sqrtf(lvlSumSq[k][c] / (float)lvlCount[k]) : 0.0f;
    	            const float gain = (k == MIC_SRC_I2S) ? srcGain[k] * outGain : 1.0f;
    	            out[k][c] = Audio_Db(rms * gain / 32768.0f);
    	            lvlSumSq[k][c] = 0.0f;
    	        }
    	        lvlCount[k] = 0;
    	    }
    	    __enable_irq();
    	    snprintf(m, sizeof(m), "level dBFS: PCM L %6.1f R %6.1f  mics L %6.1f R %6.1f | PCM gain %.1f dB\r\n",
    	             (double)out[0][0], (double)out[0][1], (double)out[1][0], (double)out[1][1],
    	             (double)Audio_Db(srcGain[MIC_SRC_I2S]));
    	    UART_Print(m);
    	}

    /* USER CODE END WHILE */

    }
}

void SystemClock_Config(void)
{
  RCC_OscInitTypeDef RCC_OscInitStruct = {0};
  RCC_ClkInitTypeDef RCC_ClkInitStruct = {0};

  /** Supply configuration update enable
  */
  HAL_PWREx_ConfigSupply(PWR_DIRECT_SMPS_SUPPLY);

  /** Configure the main internal regulator output voltage
  */
  __HAL_PWR_VOLTAGESCALING_CONFIG(PWR_REGULATOR_VOLTAGE_SCALE2);

  while(!__HAL_PWR_GET_FLAG(PWR_FLAG_VOSRDY)) {}

  /** Initializes the RCC Oscillators according to the specified parameters
  * in the RCC_OscInitTypeDef structure.
  */
  RCC_OscInitStruct.OscillatorType = RCC_OSCILLATORTYPE_HSI;
  RCC_OscInitStruct.HSIState = RCC_HSI_DIV1;
  RCC_OscInitStruct.HSICalibrationValue = RCC_HSICALIBRATION_DEFAULT;
  RCC_OscInitStruct.PLL.PLLState = RCC_PLL_ON;
  RCC_OscInitStruct.PLL.PLLSource = RCC_PLLSOURCE_HSI;
  RCC_OscInitStruct.PLL.PLLM = 4;
  RCC_OscInitStruct.PLL.PLLN = 17;
  RCC_OscInitStruct.PLL.PLLP = 2;
  RCC_OscInitStruct.PLL.PLLQ = 25;
  RCC_OscInitStruct.PLL.PLLR = 2;
  RCC_OscInitStruct.PLL.PLLRGE = RCC_PLL1VCIRANGE_3;
  RCC_OscInitStruct.PLL.PLLVCOSEL = RCC_PLL1VCOWIDE;
  RCC_OscInitStruct.PLL.PLLFRACN = 5248;
  if (HAL_RCC_OscConfig(&RCC_OscInitStruct) != HAL_OK)
  {
    Error_Handler();
  }

  /** Initializes the CPU, AHB and APB buses clocks
  */
  RCC_ClkInitStruct.ClockType = RCC_CLOCKTYPE_HCLK|RCC_CLOCKTYPE_SYSCLK
                              |RCC_CLOCKTYPE_PCLK1|RCC_CLOCKTYPE_PCLK2
                              |RCC_CLOCKTYPE_D3PCLK1|RCC_CLOCKTYPE_D1PCLK1;
  RCC_ClkInitStruct.SYSCLKSource = RCC_SYSCLKSOURCE_PLLCLK;
  RCC_ClkInitStruct.SYSCLKDivider = RCC_SYSCLK_DIV1;
  RCC_ClkInitStruct.AHBCLKDivider = RCC_HCLK_DIV1;
  RCC_ClkInitStruct.APB3CLKDivider = RCC_APB3_DIV2;
  RCC_ClkInitStruct.APB1CLKDivider = RCC_APB1_DIV4;
  RCC_ClkInitStruct.APB2CLKDivider = RCC_APB2_DIV2;
  RCC_ClkInitStruct.APB4CLKDivider = RCC_APB4_DIV2;

  if (HAL_RCC_ClockConfig(&RCC_ClkInitStruct, FLASH_LATENCY_2) != HAL_OK)
  {
    Error_Handler();
  }
}

void PeriphCommonClock_Config(void)
{
  RCC_PeriphCLKInitTypeDef PeriphClkInitStruct = {0};

  /** Initializes the peripherals clock
  */
  PeriphClkInitStruct.PeriphClockSelection = RCC_PERIPHCLK_ADC;
  PeriphClkInitStruct.PLL2.PLL2M = 4;
  PeriphClkInitStruct.PLL2.PLL2N = 10;
  PeriphClkInitStruct.PLL2.PLL2P = 2;
  PeriphClkInitStruct.PLL2.PLL2Q = 2;
  PeriphClkInitStruct.PLL2.PLL2R = 2;
  PeriphClkInitStruct.PLL2.PLL2RGE = RCC_PLL2VCIRANGE_3;
  PeriphClkInitStruct.PLL2.PLL2VCOSEL = RCC_PLL2VCOMEDIUM;
  PeriphClkInitStruct.PLL2.PLL2FRACN = 0;
  PeriphClkInitStruct.AdcClockSelection = RCC_ADCCLKSOURCE_PLL2;
  if (HAL_RCCEx_PeriphCLKConfig(&PeriphClkInitStruct) != HAL_OK)
  {
    Error_Handler();
  }
}

void Error_Handler(void)
{
    __disable_irq();
    while (1)
    {
    }
}
